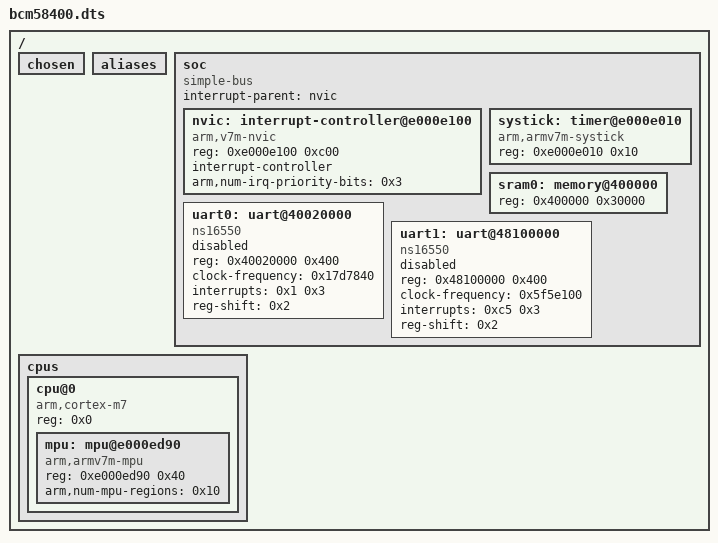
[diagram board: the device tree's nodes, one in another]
/dts-v1/;

/ {
	#address-cells = < 0x1 >;
	#size-cells = < 0x1 >;
	chosen {
	};
	aliases {
	};
	soc {
		#address-cells = < 0x1 >;
		#size-cells = < 0x1 >;
		compatible = "simple-bus";
		interrupt-parent = < &nvic >;
		ranges;
		nvic: interrupt-controller@e000e100 {
			#address-cells = < 0x1 >;
			compatible = "arm,v7m-nvic";
			reg = < 0xe000e100 0xc00 >;
			interrupt-controller;
			#interrupt-cells = < 0x2 >;
			arm,num-irq-priority-bits = < 0x3 >;
			phandle = < 0x1 >;
		};
		systick: timer@e000e010 {
			compatible = "arm,armv7m-systick";
			reg = < 0xe000e010 0x10 >;
		};
		sram0: memory@400000 {
			device_type = "memory";
			reg = < 0x400000 0x30000 >;
		};
		uart0: uart@40020000 {
			compatible = "ns16550";
			reg = < 0x40020000 0x400 >;
			clock-frequency = < 0x17d7840 >;
			interrupts = < 0x1 0x3 >;
			reg-shift = < 0x2 >;
			status = "disabled";
		};
		uart1: uart@48100000 {
			compatible = "ns16550";
			reg = < 0x48100000 0x400 >;
			clock-frequency = < 0x5f5e100 >;
			interrupts = < 0xc5 0x3 >;
			reg-shift = < 0x2 >;
			status = "disabled";
		};
	};
	cpus {
		#address-cells = < 0x1 >;
		#size-cells = < 0x0 >;
		cpu@0 {
			device_type = "cpu";
			compatible = "arm,cortex-m7";
			reg = < 0x0 >;
			#address-cells = < 0x1 >;
			#size-cells = < 0x1 >;
			mpu: mpu@e000ed90 {
				compatible = "arm,armv7m-mpu";
				reg = < 0xe000ed90 0x40 >;
				arm,num-mpu-regions = < 0x10 >;
			};
		};
	};
};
